VERSION ""

NS_ :

BS_:

BU_: K182_PACM K43_PSCM K17_EBCM NEO K124_ASCM XXX

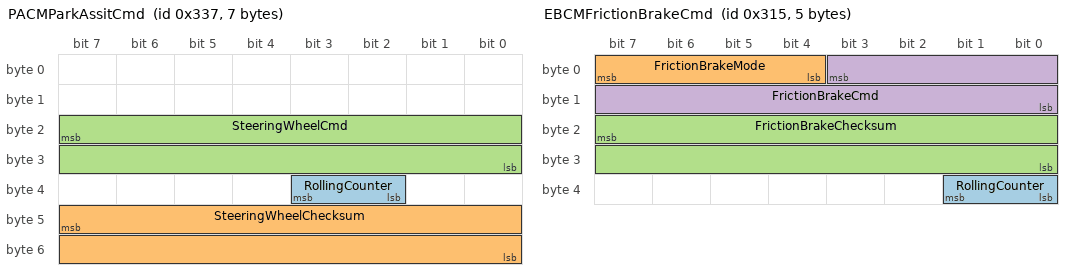
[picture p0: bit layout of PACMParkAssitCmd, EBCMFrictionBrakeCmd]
BO_ 823 PACMParkAssitCmd: 7 NEO
 SG_ RollingCounter : 35|2@0+ (1,0) [0|0] "" NEO
 SG_ SteeringWheelChecksum : 47|16@0+ (1,0) [0|0] "" NEO
 SG_ SteeringWheelCmd : 23|16@0+ (1,0) [0|0] "" NEO

BO_ 560 EBCMRegen: 6 K17_EBCM
 SG_ Regen : 1|10@0+ (1,0) [0|0] "" NEO

BO_ 368 EBCMFrictionBrakeStatus: 8 K17_EBCM
 SG_ FrictionBrakePressure : 23|16@0+ (1,0) [0|0] "" NEO

BO_ 789 EBCMFrictionBrakeCmd: 5 K17_EBCM
 SG_ RollingCounter : 33|2@0+ (1,0) [0|0] "" NEO
 SG_ FrictionBrakeMode : 7|4@0+ (1,0) [0|0] "" NEO
 SG_ FrictionBrakeChecksum : 23|16@0+ (1,0) [0|0] "" NEO
 SG_ FrictionBrakeCmd : 3|12@0- (1,0) [0|0] "" NEO

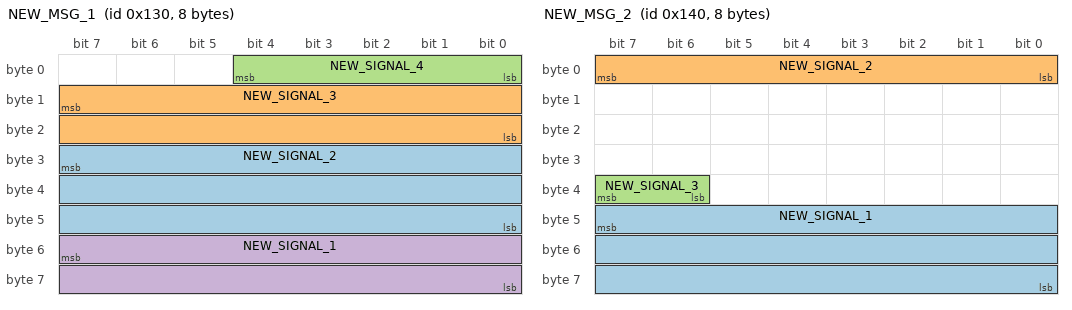
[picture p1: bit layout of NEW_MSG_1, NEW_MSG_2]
BO_ 304 NEW_MSG_1: 8 XXX
 SG_ NEW_SIGNAL_2 : 31|24@0- (1,0) [0|1] "" XXX
 SG_ NEW_SIGNAL_3 : 15|16@0- (1,0) [0|1] "" XXX
 SG_ NEW_SIGNAL_4 : 4|5@0+ (1,0) [0|1] "" XXX
 SG_ NEW_SIGNAL_1 : 55|16@0- (1,0) [0|1] "" XXX

BO_ 320 NEW_MSG_2: 8 XXX
 SG_ NEW_SIGNAL_1 : 47|24@0- (1,0) [0|1] "" XXX
 SG_ NEW_SIGNAL_2 : 7|8@0+ (1,0) [0|1] "" XXX
 SG_ NEW_SIGNAL_3 : 39|2@0+ (1,0) [0|1] "" XXX

BO_TX_BU_ 823 : K43_PSCM,NEO;
BO_TX_BU_ 789 : NEO,K17_EBCM;

CM_ BU_ K182_PACM "Parking Assist Control Module";
CM_ BU_ K43_PSCM "Power Steering Control Module";
CM_ BU_ K17_EBCM "Electronic Brake Control Module";
CM_ BU_ NEO "Comma NEO";
CM_ BU_ K124_ASCM "Active Safety Control Module";
